# STM32WBA25xx register map
File version: 1.0
Registers are 32-bit, read-write, reset 0x0 unless marked. A register's access mark holds for its fields unless they carry their own. Offsets are from the block's base; [hi:lo] are bit positions; 'fields as' and 'values as' point back to an identical list.

## RCC — Reset and Clock Control
Base 0x46020C00
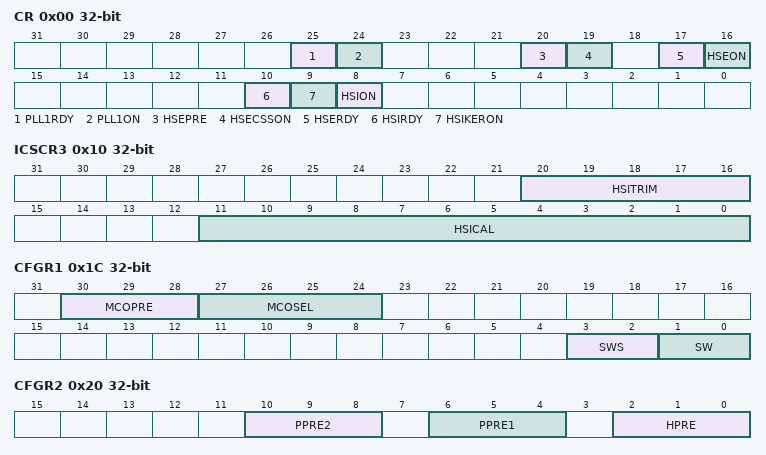
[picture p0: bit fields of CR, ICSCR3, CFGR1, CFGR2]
0x00 CR — RCC clock control register
  [25] PLL1RDY — System PLL1 clock ready
  [24] PLL1ON — System PLL1 clock enable
  [20] HSEPRE — External High Speed oscillator (HSE) clock for sysclk prescaler
  [19] HSECSSON — External High Speed oscillator (HSE) clock security system enable
  [17] HSERDY — External High Speed oscillator (HSE) clock ready
  [16] HSEON — External High Speed oscillator (HSE) clock enable
  [10] HSIRDY — Internal High Speed oscillator (HSI16) clock ready flag
  [9] HSIKERON — Internal High Speed oscillator (HSI16) clock enable for some IPs Kernel
  [8] HSION — Internal High Speed oscillator (HSI16) clock enable
0x10 ICSCR3 — RCC internal clock sources calibration register 3
  [20:16] HSITRIM — HSITRIM[4:0] bits
  [11:0] HSICAL — HSICAL[11:0] bits
0x1C CFGR1 — RCC clock configuration register 1
  [30:28] MCOPRE — MCO[220] (Prescaler)
  [27:24] MCOSEL — MCOSEL[3:0] bits (Clock output selection)
  [3:2] SWS — SWS[1:0] bits (System Clock Switch Status)
    0=HSI (HSI used as system clock); 2=HSE (HSE used as system clock); 3=PLL1R (PLL1R used as system clock)
  [1:0] SW — SW[1:0] bits (System clock Switch)
    0=HSI (HSI selection as system clock); 2=HSE (HSE selection as system clock); 3=PLL1R (PLL1R selection as system clock)
0x20 CFGR2 — RCC clock configuration register 2
  [10:8] PPRE2 — PPRE2[2:0] bits (APB2 prescaler)
    0=DIV_1 (HCLK not divided); 4=DIV_2 (HCLK divided by 2); 5=DIV_4 (HCLK divided by 4); 6=DIV_8 (HCLK divided by 8); 7=DIV_16 (HCLK divided by 16)
  [6:4] PPRE1 — PPRE1[2:0] bits (APB1 prescaler)
    values as PPRE2
  [2:0] HPRE — HPRE[2:0] bits (AHB prescaler)
    0=DIV_1 (SYSCLK not divided); 4=DIV_2 (SYSCLK divided by 2); 5=DIV_4 (SYSCLK divided by 4); 6=DIV_8 (SYSCLK divided by 8); 7=DIV_16 (SYSCLK divided by 16)
0x24 CFGR3 — RCC clock configuration register 3
  [6:4] PPRE7 — PPRE7[2:0] bits (APB7 prescaler)
    values as CFGR2.PPRE2
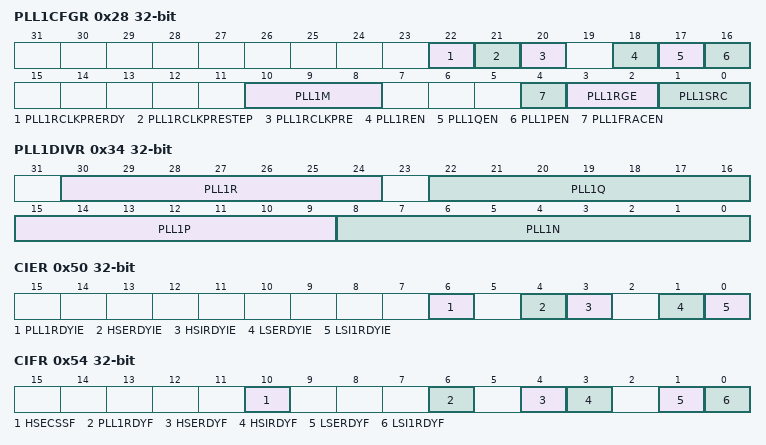
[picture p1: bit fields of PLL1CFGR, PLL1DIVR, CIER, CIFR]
0x28 PLL1CFGR — PLL1 Configuration Register
  [22] PLL1RCLKPRERDY
  [21] PLL1RCLKPRESTEP
    0=PLL1RCLK_2_STEP_DIV (PLL1RCLK 2-step division); 1=PLL1RCLK_3_STEP_DIV (PLL1RCLK 3-step division)
  [20] PLL1RCLKPRE
  [18] PLL1REN
  [17] PLL1QEN
  [16] PLL1PEN
  [10:8] PLL1M
  [4] PLL1FRACEN
  [3:2] PLL1RGE
  [1:0] PLL1SRC
    0=NONE (No clock selected as PLL1 entry clock source); 2=HSI (HSI clock selected as PLL1 entry clock source); 3=HSE (HSE clock selected as PLL1 entry clock source)
0x34 PLL1DIVR — PLL1 Dividers Configuration Register
  [30:24] PLL1R, [22:16] PLL1Q, [15:9] PLL1P, [8:0] PLL1N
0x38 PLL1FRACR — PLL1 Fractional Divider Configuration Register
  [15:3] PLL1FRACN
0x50 CIER — Clock Interrupt Enable Register
  [6] PLL1RDYIE, [4] HSERDYIE, [3] HSIRDYIE, [1] LSERDYIE, [0] LSI1RDYIE
0x54 CIFR — Clock Interrupt Flag Register
  [10] HSECSSF, [6] PLL1RDYF, [4] HSERDYF, [3] HSIRDYF, [1] LSERDYF, [0] LSI1RDYF
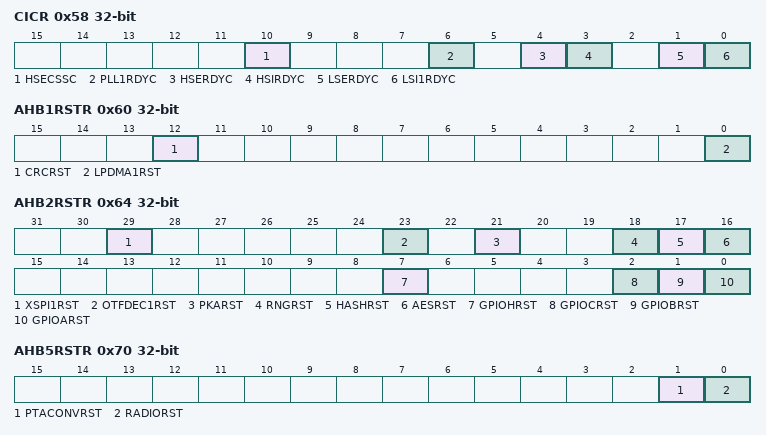
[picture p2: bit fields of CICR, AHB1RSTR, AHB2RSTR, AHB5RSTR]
0x58 CICR — Clock Interrupt Clear Register
  [10] HSECSSC, [6] PLL1RDYC, [4] HSERDYC, [3] HSIRDYC, [1] LSERDYC, [0] LSI1RDYC
0x60 AHB1RSTR — AHB1 Peripherals Reset Register
  [12] CRCRST, [0] LPDMA1RST
0x64 AHB2RSTR — AHB2 Peripherals Reset Register
  [29] XSPI1RST — XSPI1RST (XSPI1 reset)
  [23] OTFDEC1RST — OTFDEC1RST (OTFDEC1 reset)
  [21] PKARST
  [18] RNGRST
  [17] HASHRST
  [16] AESRST
  [7] GPIOHRST
  [2] GPIOCRST
  [1] GPIOBRST
  [0] GPIOARST
0x6C AHB4RSTR — AHB4 Peripherals Reset Register
  [5] ADC4RST
0x70 AHB5RSTR — AHB5 Peripherals Reset Register
  [1] PTACONVRST, [0] RADIORST
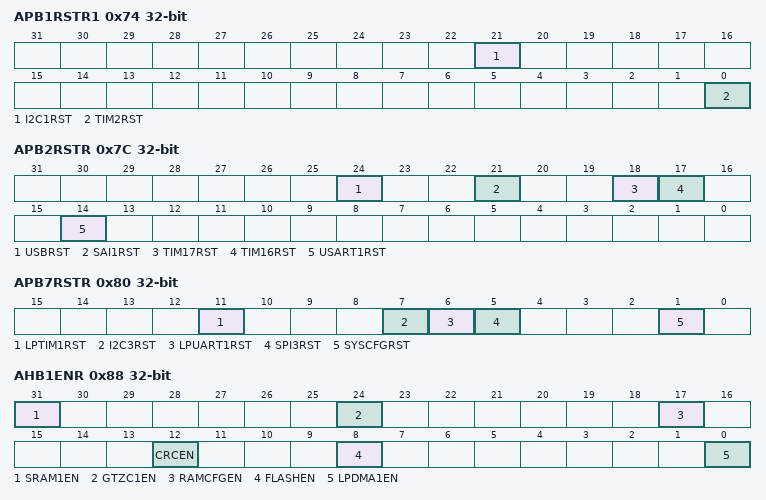
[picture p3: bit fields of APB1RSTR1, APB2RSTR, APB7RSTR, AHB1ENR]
0x74 APB1RSTR1 — APB1 Peripherals Reset Low Register
  [21] I2C1RST, [0] TIM2RST
0x78 APB1RSTR2 — APB1 Peripherals Reset High Register
  [5] LPTIM2RST
0x7C APB2RSTR — APB2 Peripherals Reset Register
  [24] USBRST — USBRST (USB reset)
  [21] SAI1RST
  [18] TIM17RST
  [17] TIM16RST
  [14] USART1RST
0x80 APB7RSTR — APB7 Peripherals Reset Register
  [11] LPTIM1RST, [7] I2C3RST, [6] LPUART1RST, [5] SPI3RST, [1] SYSCFGRST
0x88 AHB1ENR — AHB1 Peripherals Clock Enable Register
  [31] SRAM1EN, [24] GTZC1EN, [17] RAMCFGEN, [12] CRCEN, [8] FLASHEN, [0] LPDMA1EN
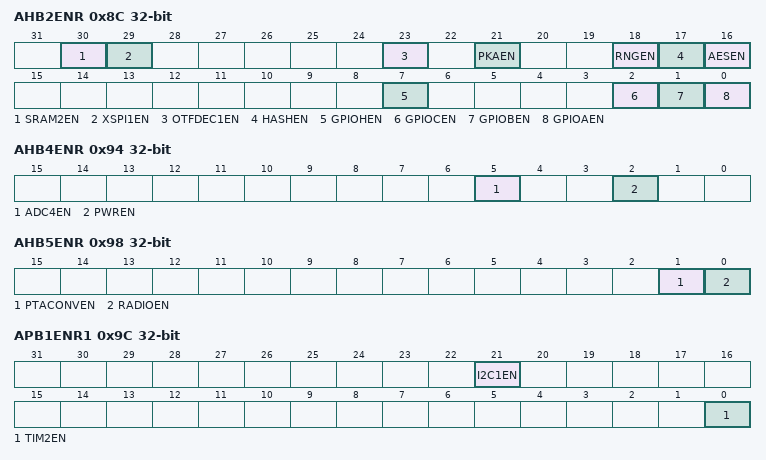
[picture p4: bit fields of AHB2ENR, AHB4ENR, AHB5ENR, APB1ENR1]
0x8C AHB2ENR — AHB2 Peripherals Clock Enable Register
  [30] SRAM2EN
  [29] XSPI1EN — XSPI1EN (XSPI1 bus clock enable)
  [23] OTFDEC1EN — OTFDEC1EN (OTFDEC1 bus clock enable)
  [21] PKAEN
  [18] RNGEN
  [17] HASHEN
  [16] AESEN
  [7] GPIOHEN
  [2] GPIOCEN
  [1] GPIOBEN
  [0] GPIOAEN
0x94 AHB4ENR — AHB4 Peripherals Clock Enable Register
  [5] ADC4EN, [2] PWREN
0x98 AHB5ENR — AHB5 Peripherals Clock Enable Register
  [1] PTACONVEN, [0] RADIOEN
0x9C APB1ENR1 — APB1 Peripherals Clock Enable Low Register
  [21] I2C1EN, [0] TIM2EN
0xA0 APB1ENR2 — APB1 Peripherals Clock Enable High Register
  [5] LPTIM2EN
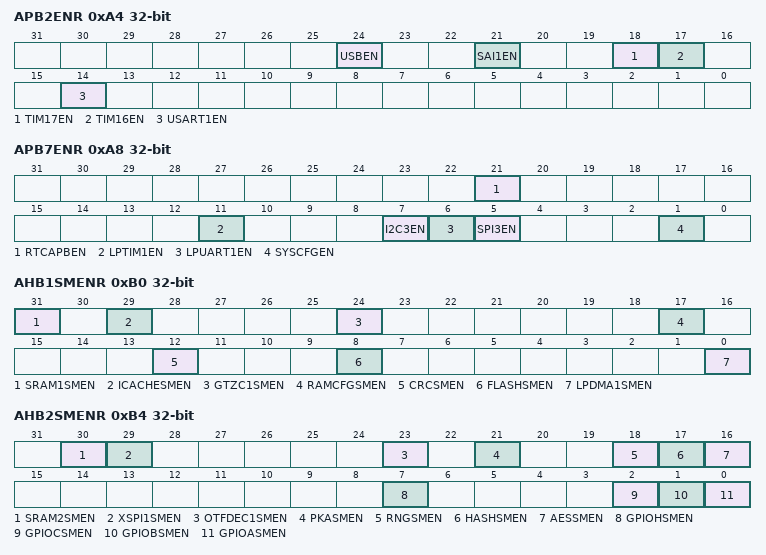
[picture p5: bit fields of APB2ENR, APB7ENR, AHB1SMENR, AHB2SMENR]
0xA4 APB2ENR — APB2 Peripherals Clock Enable Register
  [24] USBEN — USBEN (USB bus and kernel clocks enable)
  [21] SAI1EN
  [18] TIM17EN
  [17] TIM16EN
  [14] USART1EN
0xA8 APB7ENR — APB7 Peripherals Clock Enable Register
  [21] RTCAPBEN, [11] LPTIM1EN, [7] I2C3EN, [6] LPUART1EN, [5] SPI3EN, [1] SYSCFGEN
0xB0 AHB1SMENR — AHB1 Peripherals Clock Low Power Enable Register
  [31] SRAM1SMEN, [29] ICACHESMEN, [24] GTZC1SMEN, [17] RAMCFGSMEN, [12] CRCSMEN, [8] FLASHSMEN, [0] LPDMA1SMEN
0xB4 AHB2SMENR — AHB2 Peripherals Clock Low Power Enable Register
  [30] SRAM2SMEN
  [29] XSPI1SMEN — XSPI1SMEN (XSPI1 bus clock enable during Sleep and Stop modes)
  [23] OTFDEC1SMEN — OTFDEC1SMEN (OTFDEC1 bus clock enable during Sleep and Stop modes)
  [21] PKASMEN
  [18] RNGSMEN
  [17] HASHSMEN
  [16] AESSMEN
  [7] GPIOHSMEN
  [2] GPIOCSMEN
  [1] GPIOBSMEN
  [0] GPIOASMEN
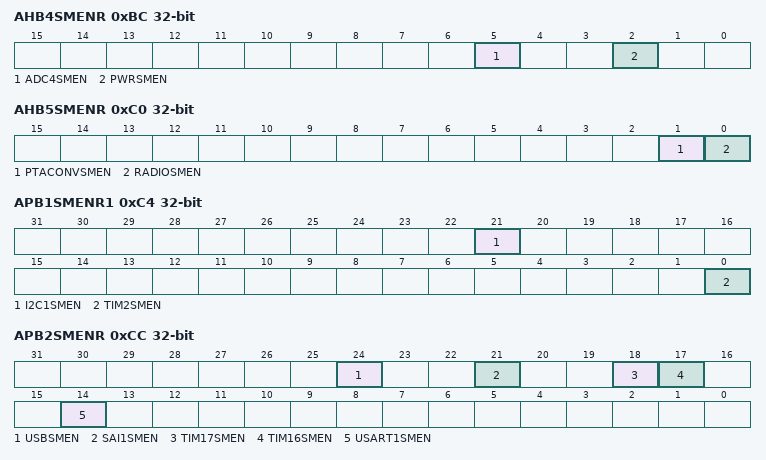
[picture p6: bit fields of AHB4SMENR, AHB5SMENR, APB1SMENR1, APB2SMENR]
0xBC AHB4SMENR — AHB4 Peripherals Clock Low Power Enable Register
  [5] ADC4SMEN, [2] PWRSMEN
0xC0 AHB5SMENR — AHB5 Peripherals Clock Low Power Enable Register
  [1] PTACONVSMEN, [0] RADIOSMEN
0xC4 APB1SMENR1 — APB1 Peripherals Clock Low Power Enable Low Register
  [21] I2C1SMEN, [0] TIM2SMEN
0xC8 APB1SMENR2 — APB1 Peripherals Clock Low Power Enable High Register
  [5] LPTIM2SMEN
0xCC APB2SMENR — APB2 Peripherals Clock Low Power Enable Register
  [24] USBSMEN — USBSMEN (USB bus and kernel clocks enable during Sleep and Stop modes)
  [21] SAI1SMEN
  [18] TIM17SMEN
  [17] TIM16SMEN
  [14] USART1SMEN
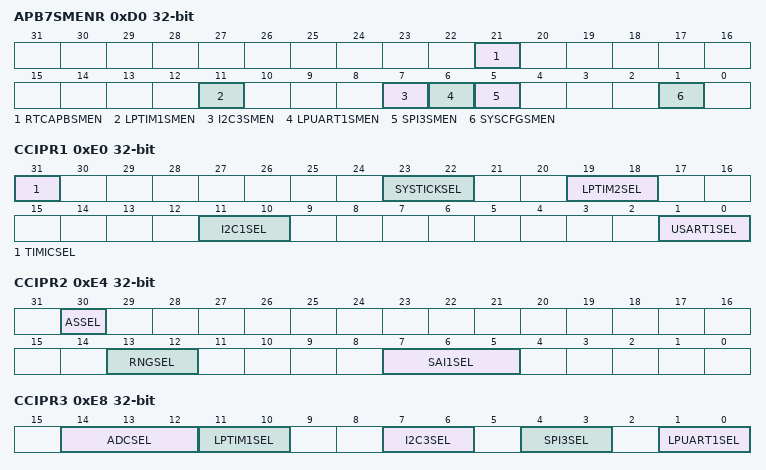
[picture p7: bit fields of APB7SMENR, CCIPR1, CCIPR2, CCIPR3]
0xD0 APB7SMENR — APB7 Peripherals Clock Low Power Enable Register
  [21] RTCAPBSMEN, [11] LPTIM1SMEN, [7] I2C3SMEN, [6] LPUART1SMEN, [5] SPI3SMEN, [1] SYSCFGSMEN
0xE0 CCIPR1 — IPs Clocks Configuration Register 1
  [31] TIMICSEL
    0=NONE (No clock available for TIM16/TIM17 and LPTIM2 input capture); 1=HSI_DIV256 (HSI/256 selected for TIM16/TIM17 and LPTIM2 input capture)
  [23:22] SYSTICKSEL
    1=LSI (LSI clock used as SYSTICK clock source); 2=LSE (LSE clock used as SYSTICK clock source); 0=HCLKDIV8 (HCLKDIV8 clock used as SYSTICK clock source); 3=HSIDIV4 (HSIDIV4 clock used as SYSTICK clock source)
  [19:18] LPTIM2SEL
  [11:10] I2C1SEL
  [1:0] USART1SEL
0xE4 CCIPR2 — IPs Clocks Configuration Register 2
  [30] ASSEL
  [13:12] RNGSEL
    0=LSE (LSE clock used as RNG clock source); 1=LSI (LSI clock used as RNG clock source); 2=HSI (HSI clock used as RNG clock source); 3=PLL1Q_DIV2 (PLL1Q/2 clock used as RNG clock source)
  [7:5] SAI1SEL
0xE8 CCIPR3 — IPs Clocks Configuration Register 3
  [14:12] ADCSEL
    0=HCLK (HCLK1 clock used as ADC4 clock source); 1=SYSCLK (SYSCLK clock used as ADC4 clock source); 2=PLL1P (PLL1P clock used as ADC4 clock source); 3=HSE (HSE clock used as ADC4 clock source); 4=HSI (HSI clock used as ADC4 clock source)
  [11:10] LPTIM1SEL
  [7:6] I2C3SEL
  [4:3] SPI3SEL
  [1:0] LPUART1SEL
    0=PCLK7 (PCLK3 clock used as LPUART1 clock source); 1=SYSCLK (SYSCLK clock used as LPUART1 clock source); 2=HSI (HSI clock used as LPUART1 clock source); 3=LSE (LSE clock used as LPUART1 clock source)
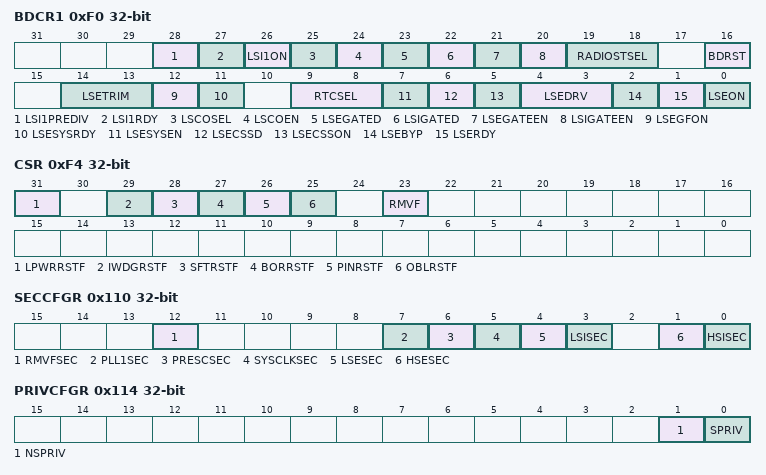
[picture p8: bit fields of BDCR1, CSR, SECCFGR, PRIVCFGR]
0xF0 BDCR1 — Backup Domain Control Register 1
  [28] LSI1PREDIV
    0=DIV_1 (LSI1 divided by 1); 1=DIV_128 (LSI1 divided by 128)
  [27] LSI1RDY
  [26] LSI1ON
  [25] LSCOSEL
    0=LSI (LSI selection for low speed clock); 1=LSE (LSE selection for low speed clock)
  [24] LSCOEN
  [23] LSEGATED — Digital domain low-speed LSE clock rated
  [22] LSIGATED — Digital domain low-speed LSI clock gated
  [21] LSEGATEEN — Digital domain low-speed LSE clock gating requested
  [20] LSIGATEEN — Digital domain low-speed LSI clock gating requested
  [19:18] RADIOSTSEL
    0=NONE (No clock selected, 2.4 GHz RADIO sleep timer kernel clock disabled); 1=LSE (LSE oscillator clock selected); 2=LSI (LSI oscillator clock selected); 3=HSE_DIV1000 (HSE oscillator clock divided by 1000 selected)
  [16] BDRST
  [14:13] LSETRIM
    0=R (Current source resistance R); 1=LSETRIMMING_3_4_R (Current source resistance 3/4 * R); 2=LSETRIMMING_2_3_R (Current source resistance 2/3 * R); 3=LSETRIMMING_1_2_R (Current source resistance 1/2 * R)
  [12] LSEGFON
  [11] LSESYSRDY
  [9:8] RTCSEL
    0=NONE (No clock used as RTC clock); 1=LSE (LSE oscillator clock used as RTC clock); 2=LSI (LSI oscillator clock used as RTC clock); 3=HSE_DIV32 (HSE oscillator clock divided by 32 used as RTC clock)
  [7] LSESYSEN
  [6] LSECSSD
  [5] LSECSSON
  [4:3] LSEDRV
    1=MEDIUMLOW (Xtal mode medium low driving capability); 2=MEDIUMHIGH (Xtal mode medium high driving capability); 3=HIGH (Xtal mode higher driving capability)
  [2] LSEBYP
  [1] LSERDY
  [0] LSEON
0xF4 CSR — V33 Clock Control & Status Register
  [31] LPWRRSTF, [29] IWDGRSTF, [28] SFTRSTF, [27] BORRSTF, [26] PINRSTF, [25] OBLRSTF, [23] RMVF
0x110 SECCFGR — RCC secure configuration register
  [12] RMVFSEC, [7] PLL1SEC, [6] PRESCSEC, [5] SYSCLKSEC, [4] LSESEC, [3] LSISEC, [1] HSESEC, [0] HSISEC
0x114 PRIVCFGR — RCC privilege configuration register
  [1] NSPRIV, [0] SPRIV
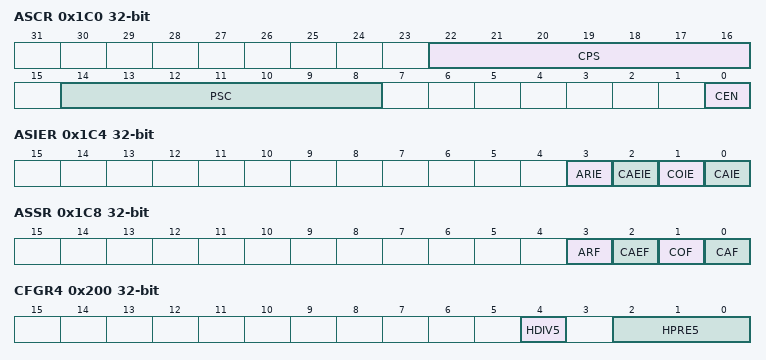
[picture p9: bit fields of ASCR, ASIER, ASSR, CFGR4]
0x1C0 ASCR — RCC privilege configuration register
  [22:16] CPS, [14:8] PSC, [0] CEN
0x1C4 ASIER — RCC privilege configuration register
  [3] ARIE — ARIE (Auto-reload interrupt enable)
  [2] CAEIE
  [1] COIE
  [0] CAIE
0x1C8 ASSR — RCC privilege configuration register
  [3] ARF — ARF (Auto-reload interrupt flag)
  [2] CAEF
  [1] COF
  [0] CAF
0x1CC ASCNTR — RCC privilege configuration register
  [19:0] CNT
0x1D0 ASARR — RCC privilege configuration register
  [19:0] AR
0x1D4 ASCAR — RCC privilege configuration register
  [26:0] CA
0x1D8 ASCOR — RCC privilege configuration register
  [19:0] CO
0x200 CFGR4 — RCC clock configuration register 4
  [4] HDIV5
    0=DIVIDER_1 (SYSCLK not divided); 1=DIVIDER_2 (SYSCLK divided by 2)
  [2:0] HPRE5
    0=DIV_1 (SYSCLK not divided); 4=DIV_2 (SYSCLK divided by 2); 5=DIV_3 (SYSCLK divided by 3); 6=DIV_4 (SYSCLK divided by 4); 7=DIV_6 (SYSCLK divided by 6)
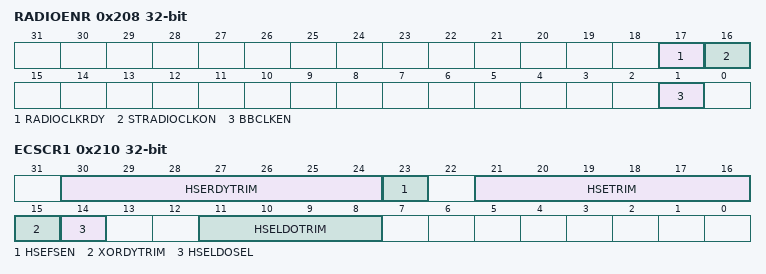
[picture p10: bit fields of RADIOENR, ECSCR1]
0x208 RADIOENR — RCC RADIO peripheral clock enable register
  [17] RADIOCLKRDY, [16] STRADIOCLKON, [1] BBCLKEN
0x210 ECSCR1 — RCC external clock sources calibration register 1
  [30:24] HSERDYTRIM — HSE32 clock ready trimming
  [23] HSEFSEN — HSE32 fast startup enable
  [21:16] HSETRIM
  [15] XORDYTRIM — XO32 clock ready trimming
  [14] HSELDOSEL — HSE32 LDO trim selection
  [11:8] HSELDOTRIM — HSE32 LDO voltage level trimming
0x220 LSIKEYR — RCC LSI key register
  [7:0] KEY — LSI1PREDIV write access enable key
